# JN5189 register map
Vendor: nxp.com; File version: 1.0
CPU: CM4 r0p1, little endian, MPU, no FPU, VTOR, 3 interrupt priority bits
Registers are 32-bit, read-write, reset 0x0 unless marked. A register's access mark holds for its fields unless they carry their own. Offsets are from the block's base; [hi:lo] are bit positions; lines under a group give offsets from that group; {n}, {i} and the like mark numbered series.

## INPUTMUX — This is the description of component input mux. . More details will follow.
Base 0x4000E000
{0xC0+4i} PINTSEL[{i}] (i=0..7) reset 0x1F — Pin interrupt select register
  [4:0] INTPIN — Pin number select for pin interrupt or pattern match engine input.
{0xE0+4i} DMA_ITRIG_INMUX[{i}] (i=0..18) reset 0x1F — Trigger select register for DMA channel. Configurable for each of the DMA channels.
  [4:0] INP — Trigger input number (decimal value) for DMA channel n (n = 0 to 17). 0: ADC0 Sequence A interrupt; 1: Reserved; 2: Timer CT32B0 Match 0; 3: Timer CT32B0 Match 1; 4: Timer CT32B1 Match 0; 5: Timer CT32B1 Match 1; 6: Pin interrupt 0; 7: Pin interrupt 1; 8: Pin interrupt 2; 9: Pin interrupt 3; 10: AES RX; 11: AES TX; 12: Hash RX; 13: Hash TX; 14: DMA output trigger mux 0; 15: DMA output trigger mux 1; 16: DMA output trigger mux 2; 17: DMA output trigger mux 3; 18- 31: reserved.
{0x160+4i} DMA_OTRIG_INMUX[{i}] (i=0..3) reset 0x1F — DMA output trigger selection to become an input to the DMA trigger mux. Four selections can be made.
  [4:0] INP — DMA trigger output number (decimal value) for DMA channel n (n = 0 to 19).
0x180 FREQMEAS_REF reset 0xF — Selection for frequency measurement reference clock
  [3:0] CLKIN — Clock source number (decimal value) for frequency measure function ref clock: 0: CLK_IN (must be enabled in functional mux); 1: XTAL 32 MHz (must be enabled in clock_ctrl); 2: FRO 1 MHz (must be enabled in clock_ctrl); 3: 32 kHz oscillator (either FRO 32 KHz or XTAL 32 KHZ); 4: Main clock (divided); 5: PIO[4] (must be configured as GPIO); 6: PIO[20] (must be configured as GPIO); 7: PIO[16] (must be configured as GPIO); 8: PIO[15] (must be configured as GPIO); 9 - 15: reserved.
0x184 FREQMEAS_TARGET reset 0xF — Selection for frequency measurement target clock
  [3:0] CLKIN — Clock source number (decimal value) for frequency measure function target clock: 0: CLK_IN (must be enabled in functional mux); 1: XTAL 32 MHz (must be enabled in clock_ctrl); 2: FRO 1 MHz (must be enabled in clock_ctrl); 3: 32 kHz oscillator (either FRO 32 KHz or XTAL 32 KHZ); 4: Main clock (divided); 5: PIO[4] (must be configured as GPIO); 6: PIO[20] (must be configured as GPIO); 7: PIO[16] (must be configured as GPIO); 8: PIO[15] (must be configured as GPIO); 9 - 15: reserved.

## GINT0 — This is the description of component gint It is an Global Interrupt with APB bus interface. More details will follow.
Base 0x40011000
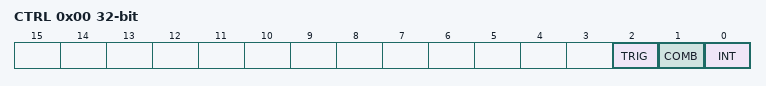
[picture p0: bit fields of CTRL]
0x00 CTRL — GPIO Grouped interrupt control register
  [2] TRIG — Group interrupt trigger. 0: Edge Triggered. 1: Level Triggered.
  [1] COMB — Combine enabled inputs for group interrupt. 0: Or, OR functionality: A grouped interrupt is generated when any one of the enabled inputs is active (based on its programmed polarity) 1: And, AND functionality: An interrupt is generated when all enabled bits are active (based on their programmed polarity)
  [0] INT — Group interrupt status. This bit is cleared by writing a one to it. Writing zero has no effect.
0x20 PORT_POL0 reset 0xFFFFFFFF — GPIO Grouped Interrupt polarity register. Configure the pin polarity of each PIO signal into the group interrupt function. If a bit is low then the corresponding PIO has an active low contribution into the group interrupt. If a bit is high then the corresponding PIO has an active high contribution.
  [21:0] POL — Configure pin polarity of pin PIOn.
0x40 PORT_ENA0 — GPIO Grouped Interrupt port enable register. When a bit is set then the corresponding PIO is enabled for the group interrupt function.
  [21:0] ENA — Enable pin PIOn for group interrupt.

## GPIO — This is the description of component gpio It is General Purpose I/O with APB bus interface. More details will follow.
Base 0x40080000
{0x0+i} B[{i}] (i=0..21) 8-bit — Byte pin registers. Read 0: pin PIOn is LOW. Read 0xFF: pin PIOn is HIGH. Only 0 or 0xFF can be read. Write 0: clear output bit. Write any value 0x01 to 0xFF: set output bit. Reset values reflects the state of pin given by the relevant bit of PIN reset value
  [7:0] B
{0x1000+4i} W[{i}] (i=0..21) — Word pin registers Read 0: pin PIOn is LOW. Read 0xFFFFFFFF: pin PIOn is HIGH. Only 0 or 0xFFFF FFFF can be read. Write 0: clear output bit. Write any value 0x00000001 to 0xFFFFFFFF: set output bit. Reset values reflects the state of pin given by the relevant bit of PIN reset value
  [31:0] W
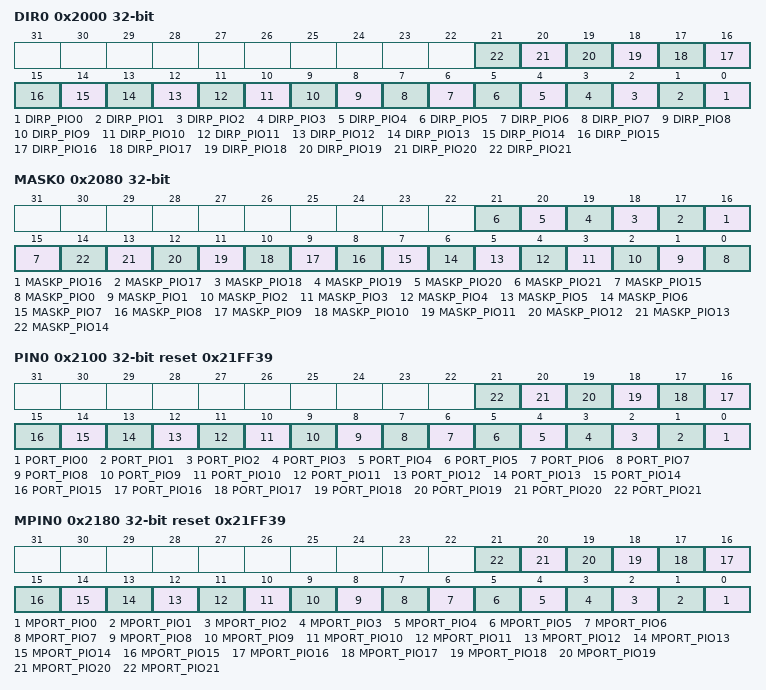
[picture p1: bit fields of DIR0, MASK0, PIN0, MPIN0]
0x2000 DIR0 — Direction register
  [n] DIRP_PIO{n} (n=0..21) — Selects pin direction for pin PIO{n} . 0 = input. 1 = output.
0x2080 MASK0 — Mask register
  [n] MASKP_PIO{n} (n=16..21) — Controls if PIO{n} is active in MPIN register. 0 = Mask bit is clear, the PIO will be active. 1 = Mask bit is set, the PIO will not be active.
  [15] MASKP_PIO15 — Controls if PIO150 is active in MPIN register. 0 = Mask bit is clear, the PIO will be active. 1 = Mask bit is set, the PIO will not be active.
  [n] MASKP_PIO{n} (n=0..14) — Controls if PIO{n} is active in MPIN register. 0 = Mask bit is clear, the PIO will be active. 1 = Mask bit is set, the PIO will not be active.
0x2100 PIN0 reset 0x21FF39 — Pin register
  [n] PORT_PIO{n} (n=0..21) — Reads pin states or loads output bits. 0 = Read: pin is low; write: clear output bit. 1 = Read: pin is high; write: set output bit.
0x2180 MPIN0 reset 0x21FF39 — Masked Pin register
  [n] MPORT_PIO{n} (n=0..21) — Masked pin register. 0 = Read: pin is LOW and/or the corresponding bit in the MASK register is 1; write: clear output bit if the corresponding bit in the MASK register is 0. 1 = Read: pin is HIGH and the corresponding bit in the MASK register is 0; write: set output bit if the corresponding bit in the MASK register is 0.
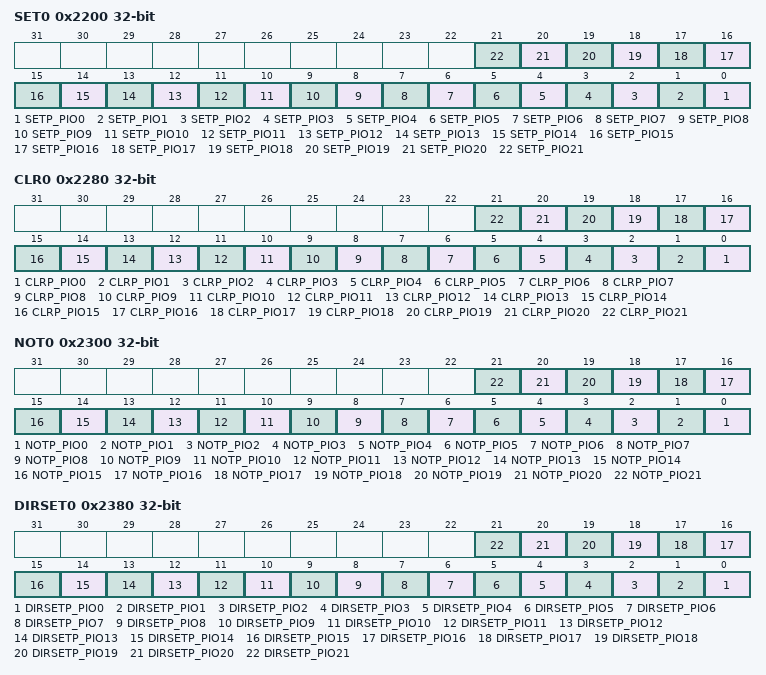
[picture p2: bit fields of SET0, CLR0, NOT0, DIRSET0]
0x2200 SET0 — Write: Set Pin register bits Read: output bits
  [n] SETP_PIO{n} (n=0..21) — Read or set output bits. 0 = Read: output bit: write: no operation. 1 = Read: output bit; write: set output bit.
0x2280 CLR0 reset not defined — Clear Pin register bits
  [n] CLRP_PIO{n} wo (n=0..21) — Clear output bits. 0 = No operation. 1 = Clear output bit.
0x2300 NOT0 reset not defined — Toggle Pin register bits
  [n] NOTP_PIO{n} wo (n=0..21) — Toggle output bits. 0 = no operation. 1 = Toggle output bit.
0x2380 DIRSET0 reset not defined — Set pin direction bits
  [n] DIRSETP_PIO{n} wo (n=0..21) — Set direction bits. 0 = no operation. 1 = Set direction bit.
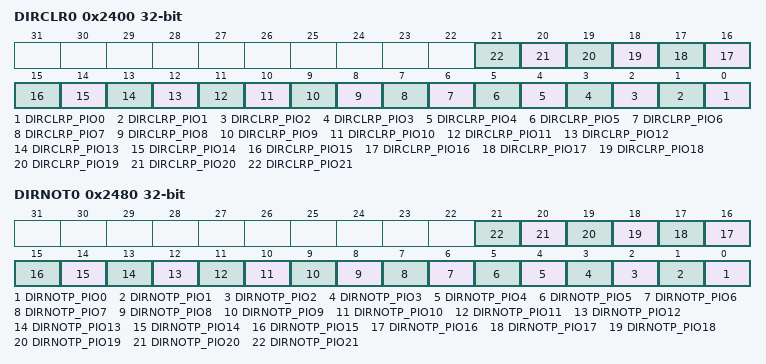
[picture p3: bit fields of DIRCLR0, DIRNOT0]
0x2400 DIRCLR0 reset not defined — Clear pin direction bits
  [n] DIRCLRP_PIO{n} wo (n=0..21) — Clear direction bits. 0 = no operation. 1 = Clear direction bit.
0x2480 DIRNOT0 reset not defined — Toggle pin direction bits
  [n] DIRNOTP_PIO{n} wo (n=0..21) — Toggle direction bits. 0 = no operation. 1 = Toggle direction bit.

## Notices in the file
Copyright 2016-2020 NXP
All rights reserved.
SPDX-License-Identifier: BSD-3-Clause
